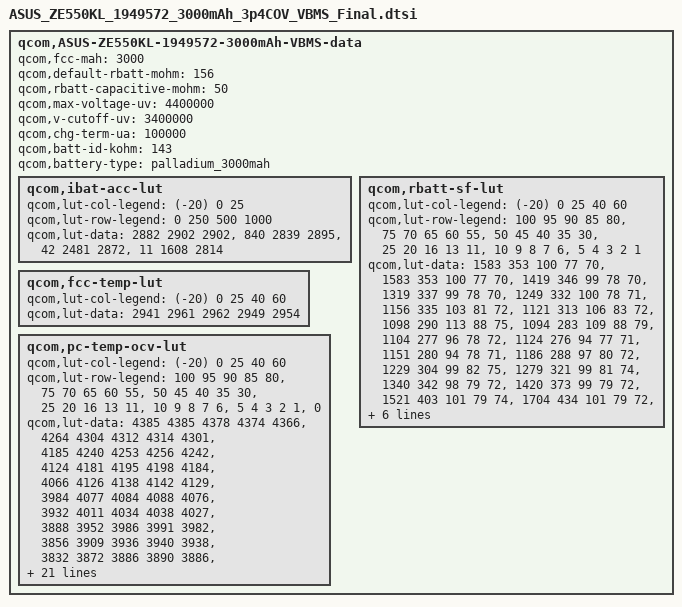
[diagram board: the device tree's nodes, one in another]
 qcom,ASUS-ZE550KL-1949572-3000mAh-VBMS-data {
	qcom,fcc-mah = <3000>;
	qcom,default-rbatt-mohm = <156>;
	qcom,rbatt-capacitive-mohm = <50>;
	qcom,max-voltage-uv = <4400000>;
	qcom,v-cutoff-uv = <3400000>;
	qcom,chg-term-ua = <100000>;
	qcom,batt-id-kohm = <143>;
	qcom,battery-type = "palladium_3000mah";

	qcom,ibat-acc-lut {
		qcom,lut-col-legend = <(-20) 0 25>;
		qcom,lut-row-legend = <0 250 500 1000>;
		qcom,lut-data = <2882 2902 2902>,
				<840 2839 2895>,
				<42 2481 2872>,
				<11 1608 2814>;
	};

	qcom,rbatt-sf-lut {
		qcom,lut-col-legend = <(-20) 0 25 40 60>;
		qcom,lut-row-legend = <100 95 90 85 80>,
				<75 70 65 60 55>,
				<50 45 40 35 30>,
				<25 20 16 13 11>,
				<10 9 8 7 6>,
				<5 4 3 2 1>;
		qcom,lut-data = <1583 353 100 77 70>,
				<1583 353 100 77 70>,
				<1419 346 99 78 70>,
				<1319 337 99 78 70>,
				<1249 332 100 78 71>,
				<1156 335 103 81 72>,
				<1121 313 106 83 72>,
				<1098 290 113 88 75>,
				<1094 283 109 88 79>,
				<1104 277 96 78 72>,
				<1124 276 94 77 71>,
				<1151 280 94 78 71>,
				<1186 288 97 80 72>,
				<1229 304 99 82 75>,
				<1279 321 99 81 74>,
				<1340 342 98 79 72>,
				<1420 373 99 79 72>,
				<1521 403 101 79 74>,
				<1704 434 101 79 72>,
				<1893 460 102 79 72>,
				<1995 472 103 81 74>,
				<2049 479 104 82 75>,
				<2094 495 106 84 78>,
				<2301 521 110 86 81>,
				<2639 550 112 87 79>,
				<3055 579 110 84 76>,
				<3612 619 112 84 76>,
				<4461 685 119 87 78>,
				<5905 781 128 93 81>,
				<10562 1562 256 133 103>;
	};

	qcom,fcc-temp-lut {
		qcom,lut-col-legend = <(-20) 0 25 40 60>;
		qcom,lut-data = <2941 2961 2962 2949 2954>;
	};

	qcom,pc-temp-ocv-lut {
		qcom,lut-col-legend = <(-20) 0 25 40 60>;
		qcom,lut-row-legend = <100 95 90 85 80>,
				<75 70 65 60 55>,
				<50 45 40 35 30>,
				<25 20 16 13 11>,
				<10 9 8 7 6>,
				<5 4 3 2 1>,
				<0>;
		qcom,lut-data = <4385 4385 4378 4374 4366>,
				<4264 4304 4312 4314 4301>,
				<4185 4240 4253 4256 4242>,
				<4124 4181 4195 4198 4184>,
				<4066 4126 4138 4142 4129>,
				<3984 4077 4084 4088 4076>,
				<3932 4011 4034 4038 4027>,
				<3888 3952 3986 3991 3982>,
				<3856 3909 3936 3940 3938>,
				<3832 3872 3886 3890 3886>,
				<3814 3840 3854 3856 3852>,
				<3798 3816 3828 3830 3826>,
				<3782 3798 3806 3809 3805>,
				<3768 3784 3789 3791 3788>,
				<3752 3772 3772 3770 3765>,
				<3736 3758 3755 3747 3738>,
				<3717 3738 3736 3726 3716>,
				<3698 3718 3716 3706 3696>,
				<3680 3703 3698 3690 3679>,
				<3664 3694 3688 3681 3671>,
				<3654 3691 3686 3680 3669>,
				<3644 3687 3684 3678 3668>,
				<3631 3682 3682 3676 3665>,
				<3614 3676 3678 3671 3661>,
				<3593 3662 3666 3657 3648>,
				<3566 3637 3638 3626 3617>,
				<3529 3595 3592 3579 3570>,
				<3478 3536 3532 3519 3510>,
				<3406 3451 3448 3437 3427>,
				<3280 3312 3314 3306 3297>,
				<3000 3000 3000 3000 3000>;
	};
};
